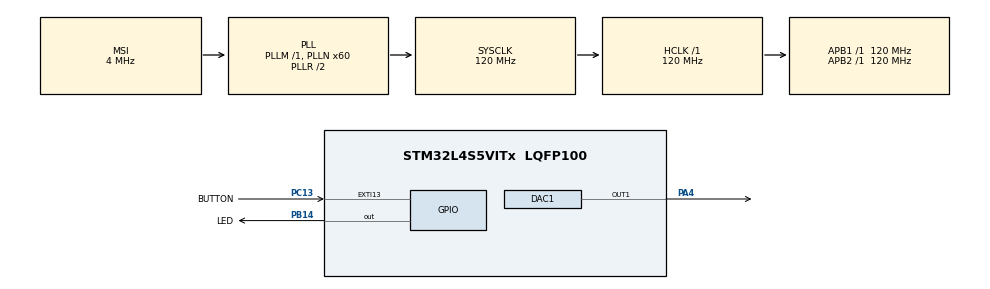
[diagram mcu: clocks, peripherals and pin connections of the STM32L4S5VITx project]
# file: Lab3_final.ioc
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DAC1.DAC_HighFrequency-DAC_OUT1=DAC_HIGH_FREQUENCY_INTERFACE_MODE_ABOVE_80MHZ
DAC1.DAC_Trigger-DAC_OUT1=DAC_TRIGGER_T2_TRGO
Dma.DAC1_CH1.0.Direction=DMA_MEMORY_TO_PERIPH
Dma.DAC1_CH1.0.EventEnable=DISABLE
Dma.DAC1_CH1.0.Instance=DMA1_Channel1
Dma.DAC1_CH1.0.MemDataAlignment=DMA_MDATAALIGN_BYTE
Dma.DAC1_CH1.0.MemInc=DMA_MINC_ENABLE
Dma.DAC1_CH1.0.Mode=DMA_CIRCULAR
Dma.DAC1_CH1.0.PeriphDataAlignment=DMA_PDATAALIGN_BYTE
Dma.DAC1_CH1.0.PeriphInc=DMA_PINC_DISABLE
Dma.DAC1_CH1.0.Polarity=HAL_DMAMUX_REQUEST_GEN_RISING
Dma.DAC1_CH1.0.Priority=DMA_PRIORITY_LOW
Dma.DAC1_CH1.0.RequestNumber=1
Dma.DAC1_CH1.0.SignalID=NONE
Dma.DAC1_CH1.0.SyncEnable=DISABLE
Dma.DAC1_CH1.0.SyncPolarity=HAL_DMAMUX_SYNC_NO_EVENT
Dma.DAC1_CH1.0.SyncRequestNumber=1
Dma.DAC1_CH1.0.SyncSignalID=NONE
Dma.Request0=DAC1_CH1
Mcu.Family=STM32L4
Mcu.Name=STM32L4S5VITx
Mcu.Package=LQFP100
NVIC.DMA1_Channel1_IRQn=true\:0\:0\:false\:false\:true\:false\:true\:true
NVIC.EXTI15_10_IRQn=true\:0\:0\:false\:false\:true\:true\:true\:true
NVIC.PriorityGroup=NVIC_PRIORITYGROUP_4
NVIC.TIM2_IRQn=true\:0\:0\:false\:false\:true\:true\:true\:true
NVIC.TIM6_DAC_IRQn=true\:0\:0\:false\:false\:true\:true\:true\:true
PA13\ (JTMS/SWDIO).Signal=SYS_JTMS-SWDIO
PA4.Signal=COMP_DAC11_group
PB14.GPIO_Label=LED
PB14.Signal=GPIO_Output
PB3\ (JTDO/TRACESWO).Signal=SYS_JTDO-SWO
PC13.GPIO_Label=BUTTON
PC13.Signal=GPXTI13
ProjectManager.HeapSize=0x200
ProjectManager.StackSize=0x400
ProjectManager.TargetToolchain=STM32CubeIDE
RCC.ADCFreq_Value=48000000
RCC.AHBFreq_Value=120000000
RCC.APB1Freq_Value=120000000
RCC.APB1TimFreq_Value=120000000
RCC.APB2Freq_Value=120000000
RCC.APB2TimFreq_Value=120000000
RCC.CortexFreq_Value=120000000
RCC.HCLKFreq_Value=120000000
RCC.HSE_VALUE=8000000
RCC.HSI48_VALUE=48000000
RCC.HSI_VALUE=16000000
RCC.LSE_VALUE=32768
RCC.MSI_VALUE=4000000
RCC.PLLN=60
RCC.PLLSAI1N=24
RCC.SYSCLKFreq_VALUE=120000000
RCC.SYSCLKSource=RCC_SYSCLKSOURCE_PLLCLK
RCC.USBFreq_Value=48000000
RCC.VCOOutputFreq_Value=240000000
SH.COMP_DAC11_group.0=DAC1_OUT1,DAC_OUT1
TIM2.Period=2721
TIM2.TIM_MasterOutputTrigger=TIM_TRGO_UPDATE
VP_TIM2_VS_ClockSourceINT.Mode=Internal
board=B-L4S5I-IOT01A

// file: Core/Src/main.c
/* USER CODE BEGIN Header */
/**
  ******************************************************************************
  * @file           : main.c
  * @brief          : Main program body
  ******************************************************************************
  * @attention
  *
  * Copyright (c) 2024 STMicroelectronics.
  * All rights reserved.
  *
  * This software is licensed under terms that can be found in the LICENSE file
  * in the root directory of this software component.
  * If no LICENSE file comes with this software, it is provided AS-IS.
  *
  ******************************************************************************
  */
/* USER CODE END Header */
#include "main.h"

/* USER CODE BEGIN Includes */
#define ARM_MATH_CM4
#include "arm_math.h"
/* USER CODE END Includes */

DAC_HandleTypeDef hdac1;
DMA_HandleTypeDef hdma_dac1_ch1;

TIM_HandleTypeDef htim2;

/* USER CODE BEGIN PV */
uint8_t sineWave;
uint8_t steps = 0;

uint8_t sine_C6[43]; //c6-> 1046.5Hz and thus 44.1kHz/1046.5Hz=43
uint8_t sine_G6[29]; //g6-> 1567.98Hz and thus 44.1kHz/1567.98Hz=29
uint8_t sine_E6[34]; //e6-> 1318.5Hz and thus 44.1kHz/1318.5Hz=34
uint8_t *currentNote = sine_C6;
/* USER CODE END PV */

void SystemClock_Config(void);
static void MX_GPIO_Init(void);
static void MX_DMA_Init(void);
static void MX_DAC1_Init(void);
static void MX_TIM2_Init(void);
/* USER CODE BEGIN PFP */
void HAL_TIM_PeriodElapsedCallback(TIM_HandleTypeDef *htim);
void HAL_GPIO_EXTI_Callback(uint16_t GPIO_Pin);
void generate_sineWave(void);
/* USER CODE END PFP */

int main(void)
{

  /* MCU Configuration--------------------------------------------------------*/

  /* Reset of all peripherals, Initializes the Flash interface and the Systick. */
  HAL_Init();

  /* Configure the system clock */
  SystemClock_Config();

  /* Initialize all configured peripherals */
  MX_GPIO_Init();
  MX_DMA_Init();
  MX_DAC1_Init();
  MX_TIM2_Init();
  /* USER CODE BEGIN 2 */

  generate_sineWave();

  //Multiple tone audio generation
  if(HAL_DAC_Start_DMA(&hdac1, DAC_CHANNEL_1, (uint32_t*)currentNote, 43, DAC_ALIGN_8B_R) != HAL_OK
		  || HAL_TIM_Base_Start_IT(&htim2) != HAL_OK) {
	  Error_Handler();
  }

//  //timer interrupt
//  if(HAL_DAC_Start(&hdac1, DAC_CHANNEL_1) != HAL_OK || HAL_TIM_Base_Start_IT(&htim2) != HAL_OK) {
//	  Error_Handler();
//  }

  /* USER CODE END 2 */

  /* Infinite loop */
  while (1)
  {

  }
}

void SystemClock_Config(void)
{
  RCC_OscInitTypeDef RCC_OscInitStruct = {0};
  RCC_ClkInitTypeDef RCC_ClkInitStruct = {0};

  /** Configure the main internal regulator output voltage
  */
  if (HAL_PWREx_ControlVoltageScaling(PWR_REGULATOR_VOLTAGE_SCALE1_BOOST) != HAL_OK)
  {
    Error_Handler();
  }

  /** Initializes the RCC Oscillators according to the specified parameters
  * in the RCC_OscInitTypeDef structure.
  */
  RCC_OscInitStruct.OscillatorType = RCC_OSCILLATORTYPE_MSI;
  RCC_OscInitStruct.MSIState = RCC_MSI_ON;
  RCC_OscInitStruct.MSICalibrationValue = 0;
  RCC_OscInitStruct.MSIClockRange = RCC_MSIRANGE_6;
  RCC_OscInitStruct.PLL.PLLState = RCC_PLL_ON;
  RCC_OscInitStruct.PLL.PLLSource = RCC_PLLSOURCE_MSI;
  RCC_OscInitStruct.PLL.PLLM = 1;
  RCC_OscInitStruct.PLL.PLLN = 60;
  RCC_OscInitStruct.PLL.PLLP = RCC_PLLP_DIV2;
  RCC_OscInitStruct.PLL.PLLQ = RCC_PLLQ_DIV2;
  RCC_OscInitStruct.PLL.PLLR = RCC_PLLR_DIV2;
  if (HAL_RCC_OscConfig(&RCC_OscInitStruct) != HAL_OK)
  {
    Error_Handler();
  }

  /** Initializes the CPU, AHB and APB buses clocks
  */
  RCC_ClkInitStruct.ClockType = RCC_CLOCKTYPE_HCLK|RCC_CLOCKTYPE_SYSCLK
                              |RCC_CLOCKTYPE_PCLK1|RCC_CLOCKTYPE_PCLK2;
  RCC_ClkInitStruct.SYSCLKSource = RCC_SYSCLKSOURCE_PLLCLK;
  RCC_ClkInitStruct.AHBCLKDivider = RCC_SYSCLK_DIV1;
  RCC_ClkInitStruct.APB1CLKDivider = RCC_HCLK_DIV1;
  RCC_ClkInitStruct.APB2CLKDivider = RCC_HCLK_DIV1;

  if (HAL_RCC_ClockConfig(&RCC_ClkInitStruct, FLASH_LATENCY_5) != HAL_OK)
  {
    Error_Handler();
  }
}

static void MX_DAC1_Init(void)
{

  DAC_ChannelConfTypeDef sConfig = {0};

  /** DAC Initialization
  */
  hdac1.Instance = DAC1;
  if (HAL_DAC_Init(&hdac1) != HAL_OK)
  {
    Error_Handler();
  }

  /** DAC channel OUT1 config
  */
  sConfig.DAC_SampleAndHold = DAC_SAMPLEANDHOLD_DISABLE;
  sConfig.DAC_Trigger = DAC_TRIGGER_T2_TRGO;
  sConfig.DAC_HighFrequency = DAC_HIGH_FREQUENCY_INTERFACE_MODE_ABOVE_80MHZ;
  sConfig.DAC_OutputBuffer = DAC_OUTPUTBUFFER_ENABLE;
  sConfig.DAC_ConnectOnChipPeripheral = DAC_CHIPCONNECT_DISABLE;
  sConfig.DAC_UserTrimming = DAC_TRIMMING_FACTORY;
  if (HAL_DAC_ConfigChannel(&hdac1, &sConfig, DAC_CHANNEL_1) != HAL_OK)
  {
    Error_Handler();
  }

}

static void MX_TIM2_Init(void)
{

  TIM_ClockConfigTypeDef sClockSourceConfig = {0};
  TIM_MasterConfigTypeDef sMasterConfig = {0};

  htim2.Instance = TIM2;
  htim2.Init.Prescaler = 0;
  htim2.Init.CounterMode = TIM_COUNTERMODE_UP;
  htim2.Init.Period = 2721;
  htim2.Init.ClockDivision = TIM_CLOCKDIVISION_DIV1;
  htim2.Init.AutoReloadPreload = TIM_AUTORELOAD_PRELOAD_DISABLE;
  if (HAL_TIM_Base_Init(&htim2) != HAL_OK)
  {
    Error_Handler();
  }
  sClockSourceConfig.ClockSource = TIM_CLOCKSOURCE_INTERNAL;
  if (HAL_TIM_ConfigClockSource(&htim2, &sClockSourceConfig) != HAL_OK)
  {
    Error_Handler();
  }
  sMasterConfig.MasterOutputTrigger = TIM_TRGO_UPDATE;
  sMasterConfig.MasterSlaveMode = TIM_MASTERSLAVEMODE_DISABLE;
  if (HAL_TIMEx_MasterConfigSynchronization(&htim2, &sMasterConfig) != HAL_OK)
  {
    Error_Handler();
  }

}

static void MX_DMA_Init(void)
{

  /* DMA controller clock enable */
  __HAL_RCC_DMAMUX1_CLK_ENABLE();
  __HAL_RCC_DMA1_CLK_ENABLE();

  /* DMA interrupt init */
  /* DMA1_Channel1_IRQn interrupt configuration */
  HAL_NVIC_SetPriority(DMA1_Channel1_IRQn, 0, 0);
  HAL_NVIC_EnableIRQ(DMA1_Channel1_IRQn);

}

static void MX_GPIO_Init(void)
{
  GPIO_InitTypeDef GPIO_InitStruct = {0};

  /* GPIO Ports Clock Enable */
  __HAL_RCC_GPIOC_CLK_ENABLE();
  __HAL_RCC_GPIOA_CLK_ENABLE();
  __HAL_RCC_GPIOB_CLK_ENABLE();

  /*Configure GPIO pin Output Level */
  HAL_GPIO_WritePin(LED_GPIO_Port, LED_Pin, GPIO_PIN_RESET);

  /*Configure GPIO pin : BUTTON_Pin */
  GPIO_InitStruct.Pin = BUTTON_Pin;
  GPIO_InitStruct.Mode = GPIO_MODE_IT_RISING;
  GPIO_InitStruct.Pull = GPIO_NOPULL;
  HAL_GPIO_Init(BUTTON_GPIO_Port, &GPIO_InitStruct);

  /*Configure GPIO pin : LED_Pin */
  GPIO_InitStruct.Pin = LED_Pin;
  GPIO_InitStruct.Mode = GPIO_MODE_OUTPUT_PP;
  GPIO_InitStruct.Pull = GPIO_NOPULL;
  GPIO_InitStruct.Speed = GPIO_SPEED_FREQ_LOW;
  HAL_GPIO_Init(LED_GPIO_Port, &GPIO_InitStruct);

  /* EXTI interrupt init*/
  HAL_NVIC_SetPriority(EXTI15_10_IRQn, 0, 0);
  HAL_NVIC_EnableIRQ(EXTI15_10_IRQn);

}

/* USER CODE BEGIN 4 */

void generate_sineWave(void) {

	// C6
	for(int i = 0; i < 43; i++) {
		sine_C6[i] = (uint8_t) ((arm_sin_f32((2*M_PI*i)/43) + 1)*(170.0f / 2.0f)); //170/2=85 (multiply 85 because that is 66% of 255)
	}
	// G6
	for(int i=0; i < 29; i++) {
		sine_G6[i] = (uint8_t) ((arm_sin_f32((2*M_PI*i)/29) + 1)*(170.0f / 2.0f));
	}
	// E6
	for(int i = 0; i < 34; i++) {
		sine_E6[i] = (uint8_t) ((arm_sin_f32((2*M_PI*i)/34) + 1)*(170.0f / 2.0f));
	}
}

//void HAL_TIM_PeriodElapsedCallback(TIM_HandleTypeDef *htim)
//{
//	if (htim->Instance == TIM2) {
//		sineWave = sine_C6[steps];
//		if(HAL_DAC_SetValue(&hdac1, DAC_CHANNEL_1, DAC_ALIGN_8B_R, sineWave) != HAL_OK){
//			Error_Handler();
//		}
//		steps++;
//		if(steps > 43) { //43 because the note playing is C6
//			steps = 0; //reset to 0
//		}
//	}
//}

void HAL_GPIO_EXTI_Callback(uint16_t GPIO_Pin){
	HAL_GPIO_TogglePin(LED_GPIO_Port, LED_Pin);
	HAL_DAC_Stop_DMA(&hdac1, DAC_CHANNEL_1);

	if(currentNote == sine_C6){
		currentNote = sine_E6;
		HAL_DAC_Start_DMA(&hdac1, DAC_CHANNEL_1, (uint32_t*)currentNote, 34, DAC_ALIGN_8B_R);
	} else if(currentNote == sine_E6){
		currentNote = sine_G6;
		HAL_DAC_Start_DMA(&hdac1, DAC_CHANNEL_1, (uint32_t*)currentNote, 29, DAC_ALIGN_8B_R);
	}else {
		currentNote = sine_C6;
		HAL_DAC_Start_DMA(&hdac1, DAC_CHANNEL_1, (uint32_t*)currentNote, 43, DAC_ALIGN_8B_R);
	}

}

/* USER CODE END 4 */

void Error_Handler(void)
{
  __disable_irq();
  while (1)
  {
  }
}
